# RZT2ME register map
Vendor: Renesas Electronics Corporation; Series: RZT; File version: 1.00.00
CPU: other r0p0, little endian, MPU, no FPU, VTOR, 4 interrupt priority bits, 624 interrupts
Registers are 32-bit, read-write, reset 0x0 unless marked. A register's access mark holds for its fields unless they carry their own. Offsets are from the block's base; [hi:lo] are bit positions; {n}, {i} and the like mark numbered series; 'fields as' and 'values as' point back to an identical list.

## GPT7 (part 1 of 2) — General PWM Timer 7
Base 0x80000000
Same registers: GPT8 0x80000100, GPT9 0x80000200, GPT10 0x80000300, GPT11 0x80000400, GPT12 0x80000500, GPT13 0x80000600, GPT0 0x90002000, GPT1 0x90002100, GPT2 0x90002200, GPT3 0x90002300, GPT4 0x90002400, GPT5 0x90002500, GPT6 0x90002600
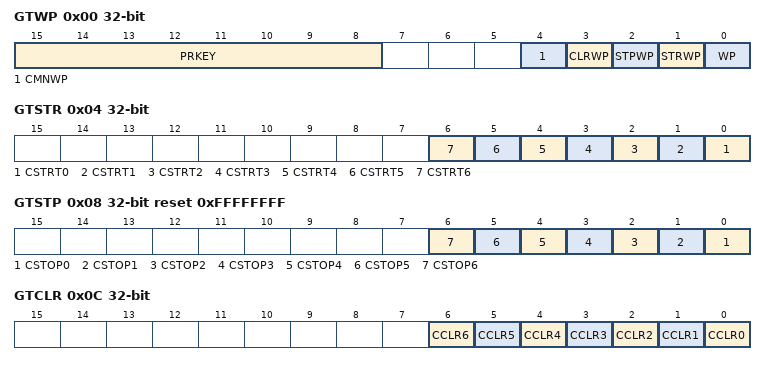
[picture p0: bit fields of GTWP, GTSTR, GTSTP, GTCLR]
0x00 GTWP — General PWM Timer Write-Protection Register
  [15:8] PRKEY wo — GTWP Key Code
  [4] CMNWP — Common Register Write Disabled
    0=Write to the register is enabled; 1=Write to the register is disabled
  [3] CLRWP — GTCLR.CCLR Bit Write Disabled
    0=Write to the bit is enabled; 1=Write to the bit is disabled
  [2] STPWP — GTSTP.CSTOP Bit Write Disabled
    values as CLRWP
  [1] STRWP — GTSTR.CSTRT Bit Write Disabled
    values as CLRWP
  [0] WP — Register Write Disabled
    values as CMNWP
0x04 GTSTR — General PWM Timer Software Start Register
  [all] fields
    0=(Reading) The counter is stopped (Writing) No effect; 1=(Reading) The counter is running (Writing) The counter starts running
  [n] CSTRT{n} (n=0..6) — Channel {n} Count Start
0x08 GTSTP reset 0xFFFFFFFF — General PWM Timer Software Stop Register
  [all] fields
    0=(Reading) The counter is operating (Writing) No effect; 1=(Reading) The counter is stopped (Writing) The counter is stopped
  [n] CSTOP{n} (n=0..6) — Channel {n} Count Stop
0x0C GTCLR wo — General PWM Timer Software Clear Register
  [all] fields
    0=The counter is not cleared; 1=The counter is cleared
  [n] CCLR{n} (n=0..6) — Channel {n} Count Clear
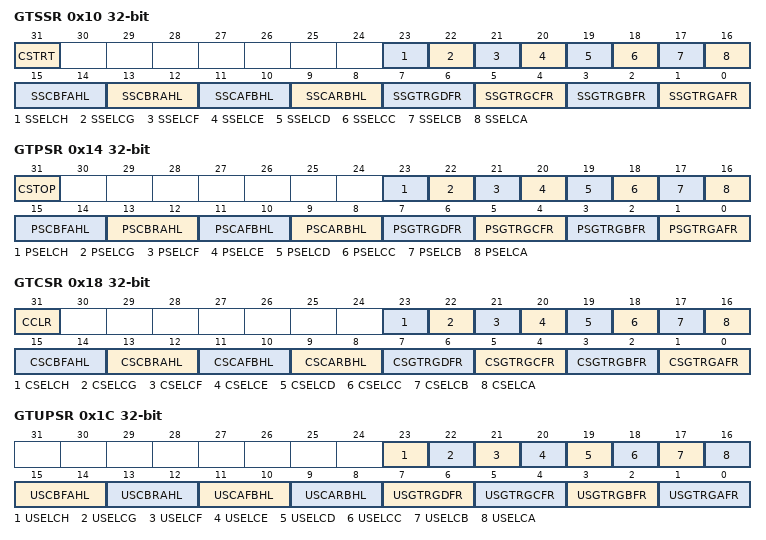
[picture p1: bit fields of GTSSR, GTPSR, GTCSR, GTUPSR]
0x10 GTSSR — General PWM Timer Start Source Select Register
  [31] CSTRT — Software Source Count Start Enable
    0=Disables count start by the GTSTR register; 1=Enables count start by the GTSTR register
  [23] SSELCH
    0=Disables count start by the LLPP GPT event H / NONSAFTY GPT event H input; 1=Enables count start by the LLPP GPT event H / NONSAFTY GPT event H input
  [22] SSELCG
    0=Disables count start by the LLPP GPT event G / NONSAFTY GPT event G input; 1=Enables count start by the LLPP GPT event G / NONSAFTY GPT event G input
  [21] SSELCF
    0=Disables count start by the LLPP GPT event F / NONSAFTY GPT event F input; 1=Enables count start by the LLPP GPT event F / NONSAFTY GPT event F input
  [20] SSELCE
    0=Disables count start by the LLPP GPT event E / NONSAFTY GPT event E input; 1=Enables count start by the LLPP GPT event E / NONSAFTY GPT event E input
  [19] SSELCD
    0=Disables count start by the LLPP GPT event D / NONSAFTY GPT event D input; 1=Enables count start by the LLPP GPT event D / NONSAFTY GPT event D input
  [18] SSELCC
    0=Disables count start by the LLPP GPT event C / NONSAFTY GPT event C input; 1=Enables count start by the LLPP GPT event C / NONSAFTY GPT event C input
  [17] SSELCB
    0=Disables count start by the LLPP GPT event B / NONSAFTY GPT event B input; 1=Enables count start by the LLPP GPT event B / NONSAFTY GPT event B input
  [16] SSELCA
    0=Disables count start by the LLPP GPT event A / NONSAFTY GPT event A input; 1=Enables count start by the LLPP GPT event A / NONSAFTY GPT event A input
  [15:14] SSCBFAHL
    0=Falling edge of the GTIOCnB signal is not used as a trigger to start counting; 1=The counter starts at a falling edge of the GTIOCnB signal while the GTIOCnA pin is driven low; 2=The counter starts at a falling edge of the GTIOCnB signal while the GTIOCnA pin is driven high; 3=The counter starts at a falling edge of the GTIOCnB signal
  [13:12] SSCBRAHL
    0=Rising edge of the GTIOCnB signal is not used as a trigger to start counting; 1=The counter starts at a rising edge of the GTIOCnB signal while the GTIOCnA pin is driven low; 2=The counter starts at a rising edge of the GTIOCnB signal while the GTIOCnA pin is driven high; 3=The counter starts at a rising edge of the GTIOCnB signal
  [11:10] SSCAFBHL
    0=Falling edge of the GTIOCnA signal is not used as a trigger to start counting; 1=The counter starts at a falling edge of the GTIOCnA signal while the GTIOCnB pin is driven low; 2=The counter starts at a falling edge of the GTIOCnA signal while the GTIOCnB pin is driven high; 3=The counter starts at a falling edge of the GTIOCnA signal
  [9:8] SSCARBHL
    0=Rising edge of the GTIOCnA signal is not used as a trigger to start counting; 1=The counter starts at a rising edge of the GTIOCnA signal while the GTIOCnB pin is driven low; 2=The counter starts at a rising edge of the GTIOCnA signal while the GTIOCnB pin is driven high; 3=The counter starts at a rising edge of the GTIOCnA signal
  [7:6] SSGTRGDFR
    0=The GTETRGD signal is not used as a trigger to start counting; 1=The counter starts at a rising edge of the GTETRGD signal; 2=The counter starts at a falling edge of the GTETRGD signal; 3=The counter starts at both edges of the GTETRGD signal
  [5:4] SSGTRGCFR
    0=The GTETRGC signal is not used as a trigger to start counting; 1=The counter starts at a rising edge of the GTETRGC signal; 2=The counter starts at a falling edge of the GTETRGC signal; 3=The counter starts at both edges of the GTETRGC signal
  [3:2] SSGTRGBFR
    0=The GTETRGB signal is not used as a trigger to start counting; 1=The counter starts at a rising edge of the GTETRGB signal; 2=The counter starts at a falling edge of the GTETRGB signal; 3=The counter starts at both edges of the GTETRGB signal
  [1:0] SSGTRGAFR
    0=The GTETRGA signal is not used as a trigger to start counting; 1=The counter starts at a rising edge of the GTETRGA signal; 2=The counter starts at a falling edge of the GTETRGA signal; 3=The counter starts at both edges of the GTETRGA signal
0x14 GTPSR — General PWM Timer Stop Source Select Register
  [31] CSTOP
    0=Disables count stop by the GTSTP register; 1=Enables count stop by the GTSTP register
  [23] PSELCH
    0=Disables count stop by the LLPP GPT event H / NONSAFTY GPT event H input; 1=Enables count stop by the LLPP GPT event H / NONSAFTY GPT event H input
  [22] PSELCG
    0=Disables count stop by the LLPP GPT event G / NONSAFTY GPT event G input; 1=Enables count stop by the LLPP GPT event G / NONSAFTY GPT event G input
  [21] PSELCF
    0=Disables count stop by the LLPP GPT event F / NONSAFTY GPT event F input; 1=Enables count stop by the LLPP GPT event F / NONSAFTY GPT event F input
  [20] PSELCE
    0=Disables count stop by the LLPP GPT event E / NONSAFTY GPT event E input; 1=Enables count stop by the LLPP GPT event E / NONSAFTY GPT event E input
  [19] PSELCD
    0=Disables count stop by the LLPP GPT event D / NONSAFTY GPT event D input; 1=Enables count stop by the LLPP GPT event D / NONSAFTY GPT event D input
  [18] PSELCC
    0=Disables count stop by the LLPP GPT event C / NONSAFTY GPT event C input; 1=Enables count stop by the LLPP GPT event C / NONSAFTY GPT event C input
  [17] PSELCB
    0=Disables count stop by the LLPP GPT event B / NONSAFTY GPT event B input; 1=Enables count stop by the LLPP GPT event B / NONSAFTY GPT event B input
  [16] PSELCA
    0=Disables count stop by the LLPP GPT event A / NONSAFTY GPT event A input; 1=Enables count stop by the LLPP GPT event A / NONSAFTY GPT event A input
  [15:14] PSCBFAHL
    0=Falling edge of the GTIOCnB signal is not used as a trigger to stop counting; 1=The counter stops at a falling edge of the GTIOCnB signal while the GTIOCnA pin is driven low; 2=The counter stops at a falling edge of the GTIOCnB signal while the GTIOCnA pin is driven high; 3=The counter stops at a falling edge of the GTIOCnB signal
  [13:12] PSCBRAHL
    0=Rising edge of the GTIOCnB signal is not used as a trigger to stop counting; 1=The counter stops at a rising edge of the GTIOCnB signal while the GTIOCnA pin is driven low; 2=The counter stops at a rising edge of the GTIOCnB signal while the GTIOCnA pin is driven high; 3=The counter stops at a rising edge of the GTIOCnB signal
  [11:10] PSCAFBHL
    0=Falling edge of the GTIOCnA signal is not used as a trigger to stop counting; 1=The counter stops at a falling edge of the GTIOCnA signal while the GTIOCnB pin is driven low; 2=The counter stops at a falling edge of the GTIOCnA signal while the GTIOCnB pin is driven high; 3=The counter stops at a falling edge of the GTIOCnA signal
  [9:8] PSCARBHL
    0=Rising edge of the GTIOCnA signal is not used as a trigger to stop counting; 1=The counter stops at a rising edge of the GTIOCnA signal while the GTIOCnB pin is driven low; 2=The counter stops at a rising edge of the GTIOCnA signal while the GTIOCnB pin is driven high; 3=The counter stops at a rising edge of the GTIOCnA signal
  [7:6] PSGTRGDFR
    0=The GTETRGD signal is not used as a trigger to stop counting; 1=The counter stops at a rising edge of the GTETRGD signal; 2=The counter stops at a falling edge of the GTETRGD signal; 3=The counter stops at both edges of the GTETRGD signal
  [5:4] PSGTRGCFR
    0=The GTETRGC signal is not used as a trigger to stop counting; 1=The counter stops at a rising edge of the GTETRGC signal; 2=The counter stops at a falling edge of the GTETRGC signal; 3=The counter stops at both edges of the GTETRGC signal
  [3:2] PSGTRGBFR
    0=The GTETRGB signal is not used as a trigger to stop counting; 1=The counter stops at a rising edge of the GTETRGB signal; 2=The counter stops at a falling edge of the GTETRGB signal; 3=The counter stops at both edges of the GTETRGB signal
  [1:0] PSGTRGAFR
    0=The GTETRGA signal is not used as a trigger to stop counting; 1=The counter stops at a rising edge of the GTETRGA signal; 2=The counter stops at a falling edge of the GTETRGA signal; 3=The counter stops at both edges of the GTETRGA signal
0x18 GTCSR — General PWM Timer Clear Source Select Register
  [31] CCLR
    0=Disables counter clear by the GTCLR register; 1=Enables counter clear by the GTCLR register
  [23] CSELCH
    0=Disables counter clear by the LLPP GPT event H / NONSAFTY GPT event H input; 1=Enables counter clear by the LLPP GPT event H / NONSAFTY GPT event H input
  [22] CSELCG
    0=Disables counter clear by the LLPP GPT event G / NONSAFTY GPT event G input; 1=Enables counter clear by the LLPP GPT event G / NONSAFTY GPT event G input
  [21] CSELCF
    0=Disables counter clear by the LLPP GPT event F / NONSAFTY GPT event F input; 1=Enables counter clear by the LLPP GPT event F / NONSAFTY GPT event F input
  [20] CSELCE
    0=Disables counter clear by the LLPP GPT event E / NONSAFTY GPT event E input; 1=Enables counter clear by the LLPP GPT event E / NONSAFTY GPT event E input
  [19] CSELCD
    0=Disables counter clear by the LLPP GPT event D / NONSAFTY GPT event D input; 1=Enables counter clear by the LLPP GPT event D / NONSAFTY GPT event D input
  [18] CSELCC
    0=Disables counter clear by the LLPP GPT event C / NONSAFTY GPT event C input; 1=Enables counter clear by the LLPP GPT event C / NONSAFTY GPT event C input
  [17] CSELCB
    0=Disables counter clear by the LLPP GPT event B / NONSAFTY GPT event B input; 1=Enables counter clear by the LLPP GPT event B / NONSAFTY GPT event B input
  [16] CSELCA
    0=Disables counter clear by the LLPP GPT event A / NONSAFTY GPT event A input; 1=Enables counter clear by the LLPP GPT event A / NONSAFTY GPT event A input
  [15:14] CSCBFAHL
    0=Falling edge of the GTIOCnB signal is not used as a trigger to clear the counter; 1=The counter is cleared at a falling edge of the GTIOCnB signal while the GTIOCnA pin is driven low; 2=The counter is cleared at a falling edge of the GTIOCnB signal while the GTIOCnA pin is driven high; 3=The counter is cleared at a falling edge of the GTIOCnB signal
  [13:12] CSCBRAHL
    0=Rising edge of the GTIOCnB signal is not used as a trigger to clear the counter; 1=The counter is cleared at a rising edge of the GTIOCnB signal while the GTIOCnA pin is driven low; 2=The counter is cleared at a rising edge of the GTIOCnB signal while the GTIOCnA pin is driven high; 3=The counter is cleared at a rising edge of the GTIOCnB signal
  [11:10] CSCAFBHL
    0=Falling edge of the GTIOCnA signal is not used as a trigger to clear the counter; 1=The counter is cleared at a falling edge of the GTIOCnA signal while the GTIOCnB pin is driven low; 2=The counter is cleared at a falling edge of the GTIOCnA signal while the GTIOCnB pin is driven high; 3=The counter is cleared at a falling edge of the GTIOCnA signal
  [9:8] CSCARBHL
    0=Rising edge of the GTIOCnA signal is not used as a trigger to clear the counter; 1=The counter is cleared at a rising edge of the GTIOCnA signal while the GTIOCnB pin is driven low; 2=The counter is cleared at a rising edge of the GTIOCnA signal while the GTIOCnB pin is driven high; 3=The counter is cleared at a rising edge of the GTIOCnA signal
  [7:6] CSGTRGDFR
    0=The GTETRGD signal is not used as a trigger to clear the counter; 1=The counter is cleared at a rising edge of the GTETRGD signal; 2=The counter is cleared at a falling edge of the GTETRGD signal; 3=The counter is cleared at both edges of the GTETRGD signal
  [5:4] CSGTRGCFR
    0=The GTETRGC signal is not used as a trigger to clear the counter; 1=The counter is cleared at a rising edge of the GTETRGC signal; 2=The counter is cleared at a falling edge of the GTETRGC signal; 3=The counter is cleared at both edges of the GTETRGC signal
  [3:2] CSGTRGBFR
    0=The GTETRGB signal is not used as a trigger to clear the counter; 1=The counter is cleared at a rising edge of the GTETRGB signal; 2=The counter is cleared at a falling edge of the GTETRGB signal; 3=The counter is cleared at both edges of the GTETRGB signal
  [1:0] CSGTRGAFR
    0=The GTETRGA signal is not used as a trigger to clear the counter; 1=The counter is cleared at a rising edge of the GTETRGA signal; 2=The counter is cleared at a falling edge of the GTETRGA signal; 3=The counter is cleared at both edges of the GTETRGA signal
0x1C GTUPSR — General PWM Timer Count-Up Source Select Register
  [23] USELCH
    0=Disables count-up by the LLPP GPT event H / NONSAFTY GPT event H input; 1=Enables count-up by the LLPP GPT event H / NONSAFTY GPT event H input
  [22] USELCG
    0=Disables count-up by the LLPP GPT event G / NONSAFTY GPT event G input; 1=Enables count-up by the LLPP GPT event G / NONSAFTY GPT event G input
  [21] USELCF
    0=Disables count-up by the LLPP GPT event F / NONSAFTY GPT event F input; 1=Enables count-up by the LLPP GPT event F / NONSAFTY GPT event F input
  [20] USELCE
    0=Disables count-up by the LLPP GPT event E / NONSAFTY GPT event E input; 1=Enables count-up by the LLPP GPT event E / NONSAFTY GPT event E input
  [19] USELCD
    0=Disables count-up by the LLPP GPT event D / NONSAFTY GPT event D input; 1=Enables count-up by the LLPP GPT event D / NONSAFTY GPT event D input
  [18] USELCC
    0=Disables count-up by the LLPP GPT event C / NONSAFTY GPT event C input; 1=Enables count-up by the LLPP GPT event C / NONSAFTY GPT event C input
  [17] USELCB
    0=Disables count-up by the LLPP GPT event B / NONSAFTY GPT event B input; 1=Enables count-up by the LLPP GPT event B / NONSAFTY GPT event B input
  [16] USELCA
    0=Disables count-up by the LLPP GPT event A / NONSAFTY GPT event A input; 1=Enables count-up by the LLPP GPT event A / NONSAFTY GPT event A input
  [15:14] USCBFAHL
    0=Falling edge of the GTIOCnB signal is not used as a trigger to increment the counter; 1=The counter is incremented at a falling edge of the GTIOCnB signal while the GTIOCnA pin is driven low; 2=The counter is incremented at a falling edge of the GTIOCnB signal while the GTIOCnA pin is driven high; 3=The counter is incremented at a falling edge of the GTIOCnB signal
  [13:12] USCBRAHL
    0=Rising edge of the GTIOCnB signal is not used as a trigger to increment the counter; 1=The counter is incremented at a rising edge of the GTIOCnB signal while the GTIOCnA pin is driven low; 2=The counter is incremented at a rising edge of the GTIOCnB signal while the GTIOCnA pin is driven high; 3=The counter is incremented at a rising edge of the GTIOCnB signal
  [11:10] USCAFBHL
    0=Falling edge of the GTIOCnA signal is not used as a trigger to increment the counter; 1=The counter is incremented at a falling edge of the GTIOCnA signal while the GTIOCnB pin is driven low; 2=The counter is incremented at a falling edge of the GTIOCnA signal while the GTIOCnB pin is driven high; 3=The counter is incremented at a falling edge of the GTIOCnA signal
  [9:8] USCARBHL
    0=Rising edge of the GTIOCnA signal is not used as a trigger to increment the counter; 1=The counter is incremented at a rising edge of the GTIOCnA signal while the GTIOCnB pin is driven low; 2=The counter is incremented at a rising edge of the GTIOCnA signal while the GTIOCnB pin is driven high; 3=The counter is incremented at a rising edge of the GTIOCnA signal
  [7:6] USGTRGDFR
    0=The GTETRGD signal is not used as a trigger to increment the counter; 1=The counter is incremented at a rising edge of the GTETRGD signal; 2=The counter is incremented at a falling edge of the GTETRGD signal; 3=The counter is incremented at both edges of the GTETRGD signal
  [5:4] USGTRGCFR
    0=The GTETRGC signal is not used as a trigger to increment the counter; 1=The counter is incremented at a rising edge of the GTETRGC signal; 2=The counter is incremented at a falling edge of the GTETRGC signal; 3=The counter is incremented at both edges of the GTETRGC signal
  [3:2] USGTRGBFR
    0=The GTETRGB signal is not used as a trigger to increment the counter; 1=The counter is incremented at a rising edge of the GTETRGB signal; 2=The counter is incremented at a falling edge of the GTETRGB signal; 3=The counter is incremented at both edges of the GTETRGB signal
  [1:0] USGTRGAFR
    0=The GTETRGA signal is not used as a trigger to increment the counter; 1=The counter is incremented at a rising edge of the GTETRGA signal; 2=The counter is incremented at a falling edge of the GTETRGA signal; 3=The counter is incremented at both edges of the GTETRGA signal
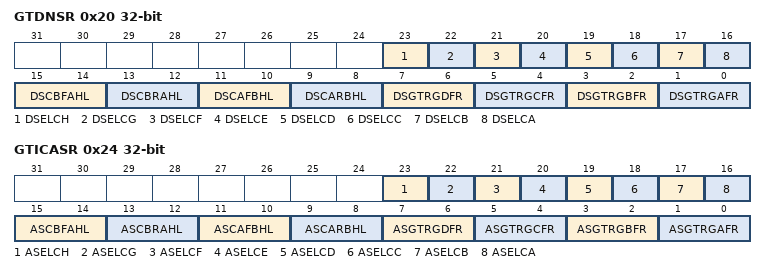
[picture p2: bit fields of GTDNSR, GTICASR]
0x20 GTDNSR — General PWM Timer Count-Down Source Select Register
  [23] DSELCH
    0=Disables count-down by the LLPP GPT event H / NONSAFTY GPT event H input; 1=Enables count-down by the LLPP GPT event H / NONSAFTY GPT event H input
  [22] DSELCG
    0=Disables count-down by the LLPP GPT event G / NONSAFTY GPT event G input; 1=Enables count-down by the LLPP GPT event G / NONSAFTY GPT event G input
  [21] DSELCF
    0=Disables count-down by the LLPP GPT event F / NONSAFTY GPT event F input; 1=Enables count-down by the LLPP GPT event F / NONSAFTY GPT event F input
  [20] DSELCE
    0=Disables count-down by the LLPP GPT event E / NONSAFTY GPT event E input; 1=Enables count-down by the LLPP GPT event E / NONSAFTY GPT event E input
  [19] DSELCD
    0=Disables count-down by the LLPP GPT event D / NONSAFTY GPT event D input; 1=Enables count-down by the LLPP GPT event D / NONSAFTY GPT event D input
  [18] DSELCC
    0=Disables count-down by the LLPP GPT event C / NONSAFTY GPT event C input; 1=Enables count-down by the LLPP GPT event C / NONSAFTY GPT event C input
  [17] DSELCB
    0=Disables count-down by the LLPP GPT event B / NONSAFTY GPT event B input; 1=Enables count-down by the LLPP GPT event B / NONSAFTY GPT event B input
  [16] DSELCA
    0=Disables count-down by the LLPP GPT event A / NONSAFTY GPT event A input; 1=Enables count-down by the LLPP GPT event A / NONSAFTY GPT event A input
  [15:14] DSCBFAHL
    0=Falling edge of the GTIOCnB signal is not used as a trigger to decrement the counter; 1=The counter is decremented at a falling edge of the GTIOCnB signal while the GTIOCnA pin is driven low; 2=The counter is decremented at a falling edge of the GTIOCnB signal while the GTIOCnA pin is driven high; 3=The counter is decremented at a falling edge of the GTIOCnB signal
  [13:12] DSCBRAHL
    0=Rising edge of the GTIOCnB signal is not used as a trigger to decrement the counter; 1=The counter is decremented at a rising edge of the GTIOCnB signal while the GTIOCnA pin is driven low; 2=The counter is decremented at a rising edge of the GTIOCnB signal while the GTIOCnA pin is driven high; 3=The counter is decremented at a rising edge of the GTIOCnB signal
  [11:10] DSCAFBHL
    0=Falling edge of the GTIOCnA signal is not used as a trigger to decrement the counter; 1=The counter is decremented at a falling edge of the GTIOCnA signal while the GTIOCnB pin is driven low; 2=The counter is decremented at a falling edge of the GTIOCnA signal while the GTIOCnB pin is driven high; 3=The counter is decremented at a falling edge of the GTIOCnA signal
  [9:8] DSCARBHL
    0=Rising edge of the GTIOCnA signal is not used as a trigger to decrement the counter; 1=The counter is decremented at a rising edge of the GTIOCnA signal while the GTIOCnB pin is driven low; 2=The counter is decremented at a rising edge of the GTIOCnA signal while the GTIOCnB pin is driven high; 3=The counter is decremented at a rising edge of the GTIOCnA signal
  [7:6] DSGTRGDFR
    0=The GTETRGD signal is not used as a trigger to decrement the counter; 1=The counter is decremented at a rising edge of the GTETRGD signal; 2=The counter is decremented at a falling edge of the GTETRGD signal; 3=The counter is decremented at both edges of the GTETRGD signal
  [5:4] DSGTRGCFR
    0=The GTETRGC signal is not used as a trigger to decrement the counter; 1=The counter is decremented at a rising edge of the GTETRGC signal; 2=The counter is decremented at a falling edge of the GTETRGC signal; 3=The counter is decremented at both edges of the GTETRGC signal
  [3:2] DSGTRGBFR
    0=The GTETRGB signal is not used as a trigger to decrement the counter; 1=The counter is decremented at a rising edge of the GTETRGB signal; 2=The counter is decremented at a falling edge of the GTETRGB signal; 3=The counter is decremented at both edges of the GTETRGB signal
  [1:0] DSGTRGAFR
    0=The GTETRGA signal is not used as a trigger to decrement the counter; 1=The counter is decremented at a rising edge of the GTETRGA signal; 2=The counter is decremented at a falling edge of the GTETRGA signal; 3=The counter is decremented at both edges of the GTETRGA signal
0x24 GTICASR — General PWM Timer Input Capture Source Select Register A
  [23] ASELCH
    0=Disables GTCCRA input capture by the LLPP GPT event H / NONSAFTY GPT event H input; 1=Enables GTCCRA input capture by the LLPP GPT event H / NONSAFTY GPT event H input
  [22] ASELCG
    0=Disables GTCCRA input capture by the LLPP GPT event G / NONSAFTY GPT event G input; 1=Enables GTCCRA input capture by the LLPP GPT event G / NONSAFTY GPT event G input
  [21] ASELCF
    0=Disables GTCCRA input capture by the LLPP GPT event F / NONSAFTY GPT event F input; 1=Enables GTCCRA input capture by the LLPP GPT event F / NONSAFTY GPT event F input
  [20] ASELCE
    0=Disables GTCCRA input capture by the LLPP GPT event E / NONSAFTY GPT event E input; 1=Enables GTCCRA input capture by the LLPP GPT event E / NONSAFTY GPT event E input
  [19] ASELCD
    0=Disables GTCCRA input capture by the LLPP GPT event D / NONSAFTY GPT event D input; 1=Enables GTCCRA input capture by the LLPP GPT event D / NONSAFTY GPT event D input
  [18] ASELCC
    0=Disables GTCCRA input capture by the LLPP GPT event C / NONSAFTY GPT event C input; 1=Enables GTCCRA input capture by the LLPP GPT event C / NONSAFTY GPT event C input
  [17] ASELCB
    0=Disables GTCCRA input capture by the LLPP GPT event B / NONSAFTY GPT event B input; 1=Enables GTCCRA input capture by the LLPP GPT event B / NONSAFTY GPT event B input
  [16] ASELCA
    0=Disables GTCCRA input capture by the LLPP GPT event A / NONSAFTY GPT event A input; 1=Enables GTCCRA input capture by the LLPP GPT event A / NONSAFTY GPT event A input
  [15:14] ASCBFAHL
    0=Falling edge of the GTIOCnB signal is not used as a trigger to capture the counter value in the GTCCRA register; 1=The counter value is captured in the GTCCRA register at a falling edge of the GTIOCnB signal while the GTIOCnA pin is driven low; 2=The counter value is captured in the GTCCRA register at a falling edge of the GTIOCnB signal while the GTIOCnA pin is driven high; 3=The counter value is captured in the GTCCRA register at a falling edge of the GTIOCnB signal
  [13:12] ASCBRAHL
    0=Rising edge of the GTIOCnB signal is not used as a trigger to capture the counter value in the GTCCRA register; 1=The counter value is captured in the GTCCRA register at a rising edge of the GTIOCnB signal while the GTIOCnA pin is driven low; 2=The counter value is captured in the GTCCRA register at a rising edge of the GTIOCnB signal while the GTIOCnA pin is driven high; 3=The counter value is captured in the GTCCRA register at a rising edge of the GTIOCnB signal
  [11:10] ASCAFBHL
    0=Falling edge of the GTIOCnA signal is not used as a trigger to capture the counter value in the GTCCRA register; 1=The counter value is captured in the GTCCRA register at a falling edge of the GTIOCnA signal while the GTIOCnB pin is driven low; 2=The counter value is captured in the GTCCRA register at a falling edge of the GTIOCnA signal while the GTIOCnB pin is driven high; 3=The counter value is captured in the GTCCRA register at a falling edge of the GTIOCnA signal
  [9:8] ASCARBHL
    0=Rising edge of the GTIOCnA signal is not used as a trigger to capture the counter value in the GTCCRA register; 1=The counter value is captured in the GTCCRA register at a rising edge of the GTIOCnA signal while the GTIOCnB pin is driven low; 2=The counter value is captured in the GTCCRA register at a rising edge of the GTIOCnA signal while the GTIOCnB pin is driven high; 3=The counter value is captured in the GTCCRA register at a rising edge of the GTIOCnA signal
  [7:6] ASGTRGDFR
    0=The GTETRGD signal is not used as a trigger to capture the counter value in the GTCCRA register; 1=The counter value is captured in the GTCCRA register at a rising edge of the GTETRGD signal; 2=The counter value is captured in the GTCCRA register at a falling edge of the GTETRGD signal; 3=The counter value is captured in the GTCCRA register at both edges of the GTETRGD signal
  [5:4] ASGTRGCFR
    0=The GTETRGC signal is not used as a trigger to capture the counter value in the GTCCRA register; 1=The counter value is captured in the GTCCRA register at a rising edge of the GTETRGC signal; 2=The counter value is captured in the GTCCRA register at a falling edge of the GTETRGC signal; 3=The counter value is captured in the GTCCRA register at both edges of the GTETRGC signal
  [3:2] ASGTRGBFR
    0=The GTETRGB signal is not used as a trigger to capture the counter value in the GTCCRA register; 1=The counter value is captured in the GTCCRA register at a rising edge of the GTETRGB signal; 2=The counter value is captured in the GTCCRA register at a falling edge of the GTETRGB signal; 3=The counter value is captured in the GTCCRA register at both edges of the GTETRGB signal
  [1:0] ASGTRGAFR
    0=The GTETRGA signal is not used as a trigger to capture the counter value in the GTCCRA register; 1=The counter value is captured in the GTCCRA register at a rising edge of the GTETRGA signal; 2=The counter value is captured in the GTCCRA register at a falling edge of the GTETRGA signal; 3=The counter value is captured in the GTCCRA register at both edges of the GTETRGA signal

## GPT14 (part 1 of 2) — General PWM Timer 14
Base 0x81000000
Same registers: GPT15 0x81000100, GPT16 0x81000200, GPT17 0x81000300
Registers as GPT7.

## Notices in the file
Copyright (c) 2020 - 2025 Renesas Electronics Corporation and/or its affiliates
SPDX-License-Identifier: BSD-3-Clause
